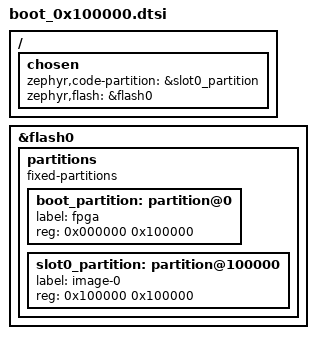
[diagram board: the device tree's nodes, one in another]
/*
 * Copyright (c) 2025 tinyVision.ai Inc.
 *
 * SPDX-License-Identifier: Apache-2.0
 */

/ {
	chosen {
		zephyr,code-partition = &slot0_partition;
		zephyr,flash = &flash0;
	};
};

&flash0 {
	partitions {
		compatible = "fixed-partitions";
		#address-cells = <1>;
		#size-cells = <1>;

		boot_partition: partition@0 {
			label = "fpga";
			reg = <0x000000 0x100000>;
		};

		slot0_partition: partition@100000 {
			label = "image-0";
			reg = <0x100000 0x100000>;
		};
	};
};
